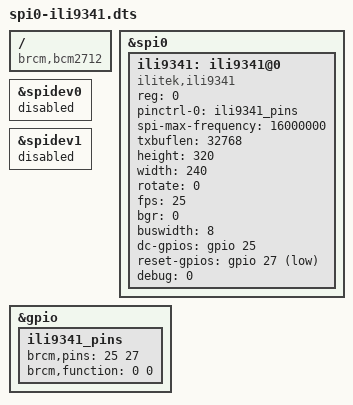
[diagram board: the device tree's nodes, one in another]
/dts-v1/;
/plugin/;

/ {
	compatible = "brcm,bcm2712";

	fragment@0 {
		target = <&spi0>;
		__overlay__ {
			status = "okay";
		};
	};

	fragment@1 {
		target = <&spidev0>;
		__overlay__ {
			status = "disabled";
		};
	};

	fragment@2 {
		target = <&spidev1>;
		__overlay__ {
			status = "disabled";
		};
	};

    fragment@3 {
        target = <&gpio>;
        __overlay__ {
            ili9341_pins: ili9341_pins {
                brcm,pins = <25 27>;
                brcm,function = <0 0>; // in
            };
        };
    };

    fragment@4 {
        target = <&spi0>;
        __overlay__ {
            status = "okay";
            #address-cells = <1>;
            #size-cells = <0>;

            ili9341: ili9341@0 {
                compatible = "ilitek,ili9341";
                reg = <0>; /* CE0 */
                pinctrl-names = "default";
                pinctrl-0 = <&ili9341_pins>;
                spi-max-frequency = <16000000>;
                txbuflen = <32768>;
                height = <320>;
                width = <240>;
                rotate = <0>;
                fps = <25>;
                bgr = <0>;
                buswidth = <8>;

                /* Pin configuration */
                dc-gpios = <&gpio 25 0>;       // GPIO24 for Data/Command
                reset-gpios = <&gpio 27 1>;    // GPIO25 for Reset
                debug = <0>;
            };
        };
    };

	__overrides__ {
		speed =   	<&ili9341>,"spi-max-frequency:0";
		txbuflen =	<&ili9341>,"txbuflen:0";
		height = 	<&ili9341>,"height:0";
		width  = 	<&ili9341>,"width:0";
		rotate =  	<&ili9341>,"rotate:0";
		fps =     	<&ili9341>,"fps:0";
		bgr =		<&ili9341>,"bgr:0";
		debug =   	<&ili9341>,"debug:0";
	};
};
